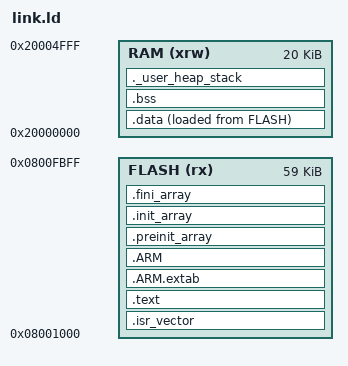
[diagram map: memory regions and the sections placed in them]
ENTRY(Reset_Handler)

_Min_Heap_Size  = 0x200;
_Min_Stack_Size = 0x600;
_estack = ORIGIN(RAM) + LENGTH(RAM);

MEMORY
{
  FLASH (rx)  : ORIGIN = 0x08001000, LENGTH = 59K
  RAM   (xrw) : ORIGIN = 0x20000000, LENGTH = 20K
}

SECTIONS
{
  .isr_vector :
  {
    . = ALIGN(4);
    KEEP(*(.isr_vector))
    . = ALIGN(4);
  } >FLASH

  .text :
  {
    . = ALIGN(4);
    *(.text)
    *(.text*)
    *(.rodata)
    *(.rodata*)
    *(.glue_7)
    *(.glue_7t)

    . = ALIGN(4);
    __rt_init_start = .;
    KEEP(*(SORT(.rti_fn*)))
    __rt_init_end = .;

    . = ALIGN(4);
    __fsymtab_start = .;
    KEEP(*(FSymTab))
    __fsymtab_end = .;
    . = ALIGN(4);
    __vsymtab_start = .;
    KEEP(*(VSymTab))
    __vsymtab_end = .;

    . = ALIGN(4);
    _etext = .;
  } >FLASH

  .ARM.extab :
  {
    *(.ARM.extab* .gnu.linkonce.armextab.*)
  } >FLASH

  .ARM :
  {
    __exidx_start = .;
    *(.ARM.exidx*)
    __exidx_end = .;
  } >FLASH

  .preinit_array :
  {
    PROVIDE_HIDDEN(__preinit_array_start = .);
    KEEP(*(.preinit_array*))
    PROVIDE_HIDDEN(__preinit_array_end = .);
  } >FLASH

  .init_array :
  {
    PROVIDE_HIDDEN(__init_array_start = .);
    KEEP(*(SORT(.init_array.*)))
    KEEP(*(.init_array*))
    PROVIDE_HIDDEN(__init_array_end = .);
  } >FLASH

  .fini_array :
  {
    PROVIDE_HIDDEN(__fini_array_start = .);
    KEEP(*(SORT(.fini_array.*)))
    KEEP(*(.fini_array*))
    PROVIDE_HIDDEN(__fini_array_end = .);
  } >FLASH

  _sidata = LOADADDR(.data);

  .data :
  {
    . = ALIGN(4);
    _sdata = .;
    *(.data)
    *(.data*)
    . = ALIGN(4);
    _edata = .;
  } >RAM AT> FLASH

  . = ALIGN(4);
  .bss :
  {
    _sbss = .;
    __bss_start__ = _sbss;
    *(.bss)
    *(.bss*)
    *(COMMON)
    . = ALIGN(4);
    _ebss = .;
    __bss_end__ = _ebss;
  } >RAM

  ._user_heap_stack :
  {
    . = ALIGN(8);
    PROVIDE(end = .);
    PROVIDE(_end = .);
    . = . + _Min_Heap_Size;
    . = . + _Min_Stack_Size;
    . = ALIGN(8);
  } >RAM

  .ARM.attributes 0 : { *(.ARM.attributes) }
}
